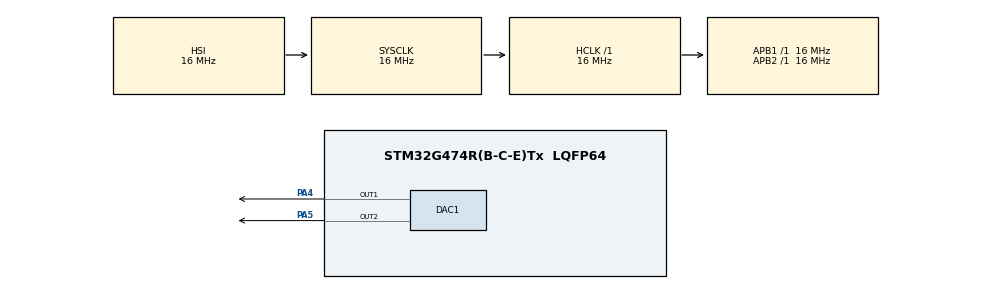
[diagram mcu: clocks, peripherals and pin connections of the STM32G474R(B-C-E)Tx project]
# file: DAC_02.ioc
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DAC1.DAC_Channel-DAC_OUT2=DAC_CHANNEL_2
Mcu.Family=STM32G4
Mcu.Name=STM32G474R(B-C-E)Tx
Mcu.Package=LQFP64
NVIC.PriorityGroup=NVIC_PRIORITYGROUP_4
PA4.Signal=COMP_DAC11_group
PA5.Signal=COMP_DAC12_group
ProjectManager.HeapSize=0x200
ProjectManager.StackSize=0x400
ProjectManager.TargetToolchain=STM32CubeIDE
RCC.ADC12Freq_Value=16000000
RCC.ADC345Freq_Value=16000000
RCC.AHBFreq_Value=16000000
RCC.APB1Freq_Value=16000000
RCC.APB1TimFreq_Value=16000000
RCC.APB2Freq_Value=16000000
RCC.APB2TimFreq_Value=16000000
RCC.CortexFreq_Value=16000000
RCC.EXTERNAL_CLOCK_VALUE=12288000
RCC.HCLKFreq_Value=16000000
RCC.HSE_VALUE=24000000
RCC.HSI48_VALUE=48000000
RCC.HSI_VALUE=16000000
RCC.LSE_VALUE=32768
RCC.PLLM=RCC_PLLM_DIV4
RCC.PLLN=85
RCC.RTCClockSelection=RCC_RTCCLKSOURCE_LSE
RCC.SYSCLKFreq_VALUE=16000000
RCC.USBFreq_Value=170000000
RCC.VCOOutputFreq_Value=340000000
SH.COMP_DAC11_group.0=DAC1_OUT1,DAC_OUT1
SH.COMP_DAC12_group.0=DAC1_OUT2,DAC_OUT2
VP_SYS_VS_DBSignals.Mode=DisableDeadBatterySignals
board=NUCLEO-G474RE

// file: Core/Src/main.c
/* USER CODE BEGIN Header */
/**
  ******************************************************************************
  * @file           : main.c
  * @brief          : Main program body
  ******************************************************************************
  * @attention
  *
  * Copyright (c) 2026 STMicroelectronics.
  * All rights reserved.
  *
  * This software is licensed under terms that can be found in the LICENSE file
  * in the root directory of this software component.
  * If no LICENSE file comes with this software, it is provided AS-IS.
  *
  ******************************************************************************
  */
/* USER CODE END Header */
#include "main.h"

/* USER CODE BEGIN PD */
uint16_t dac1, dac2;

/* USER CODE END PD */

DAC_HandleTypeDef hdac1;

void SystemClock_Config(void);
static void MX_GPIO_Init(void);
static void MX_DAC1_Init(void);

int main(void)
{

  /* MCU Configuration--------------------------------------------------------*/

  /* Reset of all peripherals, Initializes the Flash interface and the Systick. */
  HAL_Init();

  /* Configure the system clock */
  SystemClock_Config();

  /* Initialize all configured peripherals */
  MX_GPIO_Init();
  MX_DAC1_Init();
  /* USER CODE BEGIN 2 */

  // Iniciando o DAC
  HAL_DAC_Start(&hdac1, DAC_CHANNEL_1);
  HAL_DAC_Start(&hdac1, DAC_CHANNEL_2);
  /* USER CODE END 2 */

  /* Infinite loop */
  while (1)
  {

  }
}

void SystemClock_Config(void)
{
  RCC_OscInitTypeDef RCC_OscInitStruct = {0};
  RCC_ClkInitTypeDef RCC_ClkInitStruct = {0};

  /** Configure the main internal regulator output voltage
  */
  HAL_PWREx_ControlVoltageScaling(PWR_REGULATOR_VOLTAGE_SCALE1);

  /** Initializes the RCC Oscillators according to the specified parameters
  * in the RCC_OscInitTypeDef structure.
  */
  RCC_OscInitStruct.OscillatorType = RCC_OSCILLATORTYPE_HSI;
  RCC_OscInitStruct.HSIState = RCC_HSI_ON;
  RCC_OscInitStruct.HSICalibrationValue = RCC_HSICALIBRATION_DEFAULT;
  RCC_OscInitStruct.PLL.PLLState = RCC_PLL_NONE;
  if (HAL_RCC_OscConfig(&RCC_OscInitStruct) != HAL_OK)
  {
    Error_Handler();
  }

  /** Initializes the CPU, AHB and APB buses clocks
  */
  RCC_ClkInitStruct.ClockType = RCC_CLOCKTYPE_HCLK|RCC_CLOCKTYPE_SYSCLK
                              |RCC_CLOCKTYPE_PCLK1|RCC_CLOCKTYPE_PCLK2;
  RCC_ClkInitStruct.SYSCLKSource = RCC_SYSCLKSOURCE_HSI;
  RCC_ClkInitStruct.AHBCLKDivider = RCC_SYSCLK_DIV1;
  RCC_ClkInitStruct.APB1CLKDivider = RCC_HCLK_DIV1;
  RCC_ClkInitStruct.APB2CLKDivider = RCC_HCLK_DIV1;

  if (HAL_RCC_ClockConfig(&RCC_ClkInitStruct, FLASH_LATENCY_0) != HAL_OK)
  {
    Error_Handler();
  }
}

static void MX_DAC1_Init(void)
{

  DAC_ChannelConfTypeDef sConfig = {0};

  /** DAC Initialization
  */
  hdac1.Instance = DAC1;
  if (HAL_DAC_Init(&hdac1) != HAL_OK)
  {
    Error_Handler();
  }

  /** DAC channel OUT1 config
  */
  sConfig.DAC_HighFrequency = DAC_HIGH_FREQUENCY_INTERFACE_MODE_AUTOMATIC;
  sConfig.DAC_DMADoubleDataMode = DISABLE;
  sConfig.DAC_SignedFormat = DISABLE;
  sConfig.DAC_SampleAndHold = DAC_SAMPLEANDHOLD_DISABLE;
  sConfig.DAC_Trigger = DAC_TRIGGER_NONE;
  sConfig.DAC_Trigger2 = DAC_TRIGGER_NONE;
  sConfig.DAC_OutputBuffer = DAC_OUTPUTBUFFER_ENABLE;
  sConfig.DAC_ConnectOnChipPeripheral = DAC_CHIPCONNECT_EXTERNAL;
  sConfig.DAC_UserTrimming = DAC_TRIMMING_FACTORY;
  if (HAL_DAC_ConfigChannel(&hdac1, &sConfig, DAC_CHANNEL_1) != HAL_OK)
  {
    Error_Handler();
  }

  /** DAC channel OUT2 config
  */
  if (HAL_DAC_ConfigChannel(&hdac1, &sConfig, DAC_CHANNEL_2) != HAL_OK)
  {
    Error_Handler();
  }

}

static void MX_GPIO_Init(void)
{

  /* GPIO Ports Clock Enable */
  __HAL_RCC_GPIOA_CLK_ENABLE();

}

void Error_Handler(void)
{
  __disable_irq();
  while (1)
  {
  }
}
